# M2Sxxx register map
Vendor: Microsemi; Series: SmartFusion2; File version: 2.0.32
CPU: CM3 r2p1, little endian, MPU, no FPU, 4 interrupt priority bits
Registers are 32-bit, read-write, no defined reset value unless marked. A register's access mark holds for its fields unless they carry their own. Offsets are from the block's base; [hi:lo] are bit positions; {n}, {i} and the like mark numbered series.

## SPI_0 — No description provided for this peripheral
Base 0x40001000
Same registers: SPI_1 0x40011000
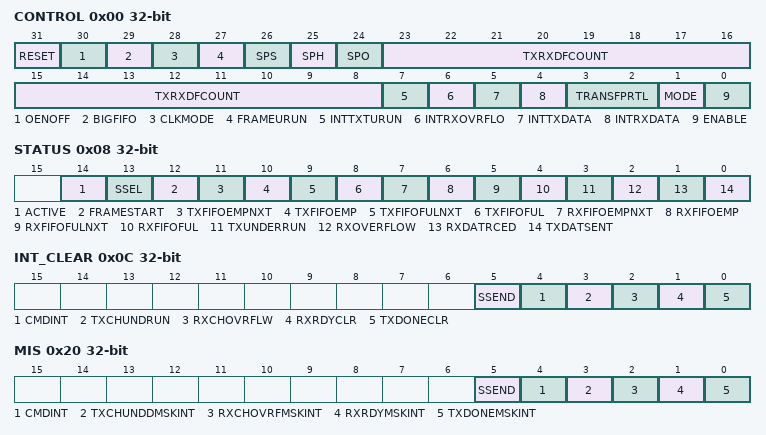
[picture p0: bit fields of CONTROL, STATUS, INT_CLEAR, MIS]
0x00 CONTROL
  [31] RESET — 0: SPI is enabled 1: SPI is held in Power reset state.
  [30] OENOFF — 0: SPI output enable active as required 1: SPI output enable is not asserted. Allows multiple slaves to share a single slave select signal with a single master.
  [29] BIGFIFO — Alters FIFO depth when frame size is [4-8] bits. 0: FIFO depth is 4 frames. 1: FIFO depth is 32 frames when frame size is [9-16] bits FIFO depth is 16; and when frame size is [17-32] bits FIFO depth is 8.
  [28] CLKMODE — Specifies the methodology used to calculate the SPICLK divider. 0: SPICLK = 1 / (2 CLK_GEN + 1) where CLK_GEN = 0 to 15. 1: SPICLK = 1 / (2 * (CLK_GEN + 1)) where CLK_GEN = 0 to 255.
  [27] FRAMEURUN — 0: The under-runs are generated whenever a read is attempted from an empty transmit FIFO. 1: The under-run condition will be ignored for the complete frame, if the first data frame read resulted in a potential overflow; that is, the slave was not ready to transmit any data. If the first data frame is read from the FIFO and transmitted, an under-run will be generated, when the FIFO becomes empty for any of the remaining packet frames (that is, while SSEL is active). Master operation does not create a transmit FIFO under-run condition.
  [26] SPS — Defines slave select behavior.
  [25] SPH — Clock phase
  [24] SPO — Clock polarity
  [23:8] TXRXDFCOUNT — Number of data frames to be sent or received. Counts from 1. Maximum value is 64K.
  [7] INTTXTURUN — Interrupt on transmit the under-run 0: Interrupt disabled 1: Interrupt enabled
  [6] INTRXOVRFLO — Interrupt on receive overflow 0: Interrupt disable 1: Interrupt enabled
  [5] INTTXDATA — Interrupt on transmit data 0: Interrupt disabled 1: Interrupt enabled
  [4] INTRXDATA — Interrupt on receive data 0: Interrupt disabled 1: Interrupt enabled
  [3:2] TRANSFPRTL — Transfer protocol Decode: 0b00: Motorola SPI 0b01: TI synchronous serial 0b10: National Semiconductor MICROWIRE 0b11: Reserved Note: The transfer protocol cannot be changed while the SPI is enabled.
  [1] MODE — SPI implementation 0: Slave 1: Master (default)
  [0] ENABLE — Core enable 0: Disable (default) 1: Enable The core will not respond to external signals (SPI_X_DI,SPI_X_DO) until this bit is enabled. SPI_X_CLK is driven low and SPI_X_OEN and SPI_X_SS (slave select) are driven inactive.
0x04 TXRXDF_SIZE — Transmit and receive data frame size
  [5:0] TXRXDFS — Transmit and receive data size. Maximum value is 32. Number of bits shifted out and received per frame (count starts from 1). In National Semiconductor MICROWIRE mode, this is the number of shifts to be done after the control byte is sent. Note: This register must be set before SPI is enabled. Writes to this register are ignored after the SPI is enabled.
0x08 STATUS
  [14] ACTIVE ro — SPI is still transmitting or receiving data.
  [13] SSEL ro — Current state of SPI_X_SS[0]
  [12] FRAMESTART ro — 0: SPI output enable is active as required. 1: SPI output enable is not asserted. Allows multiple slaves to share a single slave select signal with a single master.
  [11] TXFIFOEMPNXT ro — Transmit FIFO empty on next read
  [10] TXFIFOEMP ro — Transmit FIFO is empty
  [9] TXFIFOFULNXT ro — Transmit FIFO full on next write
  [8] TXFIFOFUL ro — Transmit FIFO is full
  [7] RXFIFOEMPNXT ro — Receive FIFO empty on next read
  [6] RXFIFOEMP ro — Receive FIFO empty
  [5] RXFIFOFULNXT ro — Receive FIFO full on next write
  [4] RXFIFOFUL ro — Receive FIFO is full
  [3] TXUNDERRUN ro — No data available for transmission. The channel cannot read data from the transmit FIFO because the transmit FIFO is empty. Certainly this can only be raised in Slave mode because the master will not attempt to transmit unless there is data in FIFO.
  [2] RXOVERFLOW ro — Channel is unable to write to receive FIFO as it is full. Applies to Master and Slave modes.
  [1] RXDATRCED ro — When set, it indicates that the number of frames specified by TxRXDFCOUNT has been received and can be read. Applies to Master and Slave modes.
  [0] TXDATSENT ro — When set, it indicates that the numbers of frames specified by TxRXDFCOUNT has been sent. Applies to Master and Slave modes.
0x0C INT_CLEAR — Interrupt clear register
  [5] SSEND — Write one to clear the interrupt
  [4] CMDINT — Write one to clear the interrupt
  [3] TXCHUNDRUN wo — Transmit channel under-run
  [2] RXCHOVRFLW wo — Receive channel over flow
  [1] RXRDYCLR wo — Clears receive ready (RX_RDY)
  [0] TXDONECLR wo — Clears transmit done (TX_DONE)
0x10 RX_DATA — Receive data register
  [31:0] RXDATA ro — Received data. Reading this clears the register of the received data.
0x14 TX_DATA — Transmit data register
  [31:0] TXDATA wo — Data to be transmitted. Writing to this clears the last data transmitted.
0x18 CLK_GEN — Output clock generator (Master mode)
  [7:0] CLK_GEN — Specifies the methodology used to calculate the SPICLK divider. CLK_MODE = 0: SPICLK = 1 / (2^(CLK_GEN + 1)) where CLK_GEN = 0 to 15. CLK_MODE = 1: SPICLK = 1 / (2 * CLK_GEN + 1) where CLK_GEN = 0 to 255.
0x1C SLAVE_SELECT — Specifies slave selected (Master mode)
  [7:0] SLAVESELECT — Specifies the slave selected. Writing one to a bit position selects the corresponding slave. SLAVESELECT[7:1] are available at the FPGA fabric interface, while SLAVESELECT[0] is available at the SPI_X_SS[0] pin. Note: The slave select output signal is active low.
0x20 MIS — Masked interrupt status
  [5] SSEND ro — Equals RIS[5] and CONTROL2[5]. When this is high, the interrupt is active.
  [4] CMDINT ro — Equals RIS[4] and CONTROL2[4]. When this is high, the interrupt is active.
  [3] TXCHUNDDMSKINT ro — Masked interrupt status. Reading this returns interrupt status. Masked interrupt status = Raw interrupt status and interrupt mask (Control Register). MIS = RIS and CONTROL[7:4]. Masked status of transmit channel under-run TXCHUNDMSKINT=TXCHUNDRINT and INTTXUNRRUN
  [2] RXCHOVRFMSKINT ro — Masked status of receive channel overflow. RXCHOVRFMSKINT = RXCHOVRFINT and INTRXOVRFLO
  [1] RXRDYMSKINT ro — Masked status of receive data ready (data received in FIFO). RXRDYMSKINT = RXRDY and INTTXDATA
  [0] TXDONEMSKINT ro — Masked status of transmit done (data shifted out) TXDONEMSKINT = TXDONE and INTRXDATA
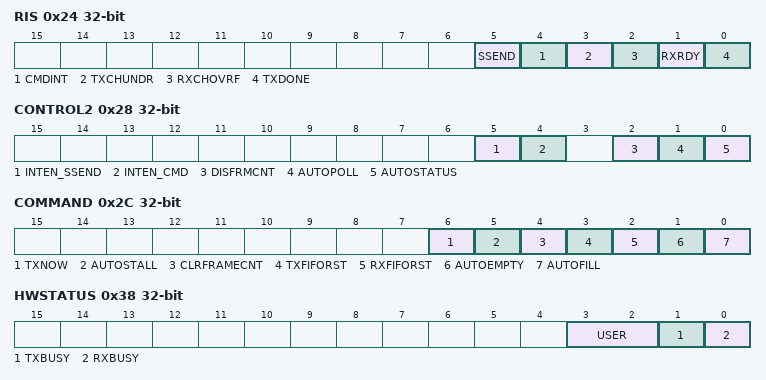
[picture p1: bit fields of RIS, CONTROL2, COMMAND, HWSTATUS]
0x24 RIS — Raw interrupt status
  [5] SSEND — Indicates that SPI_X_SS[x] has gone inactive.
  [4] CMDINT — Indicates that the number of frames set by the CMDSIZE register has been received as a single packet of frames (SPI_X_SS[x] held active).
  [3] TXCHUNDR ro — RAW interrupt status. Reading this returns raw interrupt status. Raw status of transmit channel under-run
  [2] RXCHOVRF ro — Raw status of receive channel overflow
  [1] RXRDY ro — Receive data ready (data received in FIFO)
  [0] TXDONE ro — Raw status of transmit done (data shifted out)
0x28 CONTROL2 — Control bits for enhanced modes
  [5] INTEN_SSEND — Indicates that SPI_X_SS[x] has gone inactive.
  [4] INTEN_CMD — Indicates that the number of frames set by the CMDSIZE register have been received as a single packet of frames (SPI_X_SS[x] held active).
  [2] DISFRMCNT — 0: The internal frame counter is active. When the counter reaches the programmed limit, it will pause the current SPI transfer inserting idle cycles and generate the appropriate interrupts. 1: The internal frame counter is not active.The core transmits data until the transmit FIFO empties. The FRAMECNT (CONTROL register) should also be programmed to zero.
  [1] AUTOPOLL — 0: No effect 1: The first receive frame after SPI_X_SS[0] is active. It is discarded (not written to the FIFO) and supports the POLL function.
  [0] AUTOSTATUS — 0: No effect 1: The first transmitted frame (Slave mode) contains the hardware status, not data from the transmit FIFO.
0x2C COMMAND
  [6] TXNOW — 0: No effect 1: Writing one clears the TxBUSY bit in Slave mode immediately rather than waiting for PKTSIZE frames to be available, telling the master that there is data available. This is intended to use when less than the programmed PKTSIZE data frames are being transmitted, removing the requirement to transmit PKTSIZE frames. This bit stays set until the first data frame is transmitted.
  [5] AUTOSTALL — 0: No effect 1: Writing one will cause the master to delay transmission until the transmit FIFO contains the number of frames specified by the PKTSIZE register. This guarantee that the frames are transmitted with no idle cycles or time gaps between them. This bit will be automatically cleared as soon as the core starts transmitting the frames.
  [4] CLRFRAMECNT — 0: No effect 1: Writing one clears the internal frame counter. This bit always reads as zero. The counter is also cleared when the core is disabled, CTL1, or CTL2 are written (that is, the frame count limit changed).
  [3] TXFIFORST — 0: No effect 1: Writing one resets the Tx FIFO. This bit always reads as zero.
  [2] RXFIFORST — 0: No effect Writing one resets the Rx FIFO. This bit always reads as zero.
  [1] AUTOEMPTY — 0: No effect 1: Writing one causes the SPI core to automatically discard any further received data until the number of frames requested in the FRAMECNT register has been received or (in Slave mode) SSEL goes inactive. This bit will stay set until all the frames are complete or it is cleared.
  [0] AUTOFILL — 0: No effect 1: Writing one causes the SPI core to automatically fill the transmit FIFO with zeros to match the number of frames requested in the FRAMECNT register. Typically, the five command bytes must be written to the TxDATA register and then this bit must be set. Data can be read from the receive FIFO until the complete set of frames has been read. This bit will stay set until all the frames are complete or it is cleared.
0x30 PKTSIZE — Packet size
  [7:0] PKTSIZE — Sets the size of the SPI CMD/data frame. PKTSIZE cannot be greater than the FIFO size.
0x34 CMD_SIZE — Command size
  [7:0] CMDSIZE — Number of frames after SPI_SS[0] going active that the CMD interrupt should be generated. Note: This controls the RxCMD interrupt. The internal counters count frames from SPI_SS[0] going low. It automatically resets and starts counting again once SSEL goes inactive. In TI mode, back- to-back frames are counted, any gaps in data causes the counter to start counting again.
0x38 HWSTATUS — Slave hardware status
  [3:2] USER — These bits are set by the CPU. Their function is undefined but could be used to send additional status or request information to the master.
  [1] TXBUSY — 0: Master may request the requested data. There are PKTSIZE frames of data in the transmit FIFO (when AUTOPOLL is set to PKTSIZE - 1) 1: Indicates not ready to transmit data.
  [0] RXBUSY — 1: Indicates that the receive buffer is busy (not empty). 0: Indicates that up to PKTSIZE frames of command followed by data may be sent to the slave.
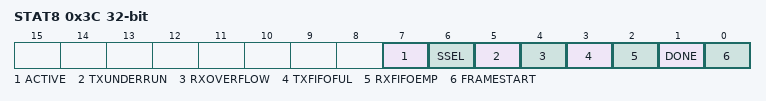
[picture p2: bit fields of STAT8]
0x3C STAT8 — Status register
  [7] ACTIVE ro — SPI is still transmitting the data
  [6] SSEL ro — Current state of SPI_X_SS[0]
  [5] TXUNDERRUN ro — Transmit FIFO underflowed
  [4] RXOVERFLOW ro — Receive FIFO overflowed
  [3] TXFIFOFUL ro — Transmit FIFO is full
  [2] RXFIFOEMP ro — Receive FIFO is empty
  [1] DONE ro — The number of request frames have been transmitted and received.
  [0] FRAMESTART ro — Next frame in receive FIFO was received after SPI_X_SS[x] went active (command frame).
{0x40+4i} CTRL{i} (i=0..2) — No description provided for this register
  [31:0] CTRL{i} — Aliased CONTROL register bits {8i+7}:{8i}. This register allows byte operations from an 8-bit processor in the fabric. It is not intended for access from internal MSS masters.
0x4C CTRL3 — No description provided for this register
  [31:0] CTRL3 — Aliased CONTROL register bits 25:24. This register allows byte operations from an 8-bit processor in the fabric. It is not intended for access from internal MSS masters.

## Notices in the file
(c) Copyright 2009-2015 Microsemi  SoC Products Group.  All rights reserved.
